# WB32F10x register map
File version: 1.2
CPU: CM3 r2p0, little endian, MPU, no FPU, 4 interrupt priority bits
Registers are 32-bit, read-write, reset 0x0 unless marked. A register's access mark holds for its fields unless they carry their own. Offsets are from the block's base; [hi:lo] are bit positions; {n}, {i} and the like mark numbered series.

## USB — Universal Serial Bus
Base 0x40014000
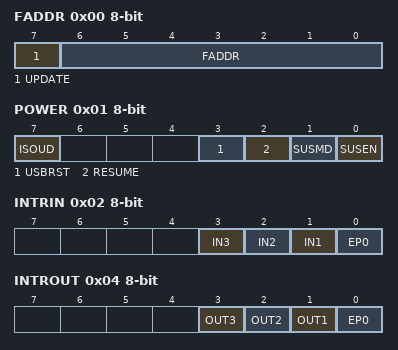
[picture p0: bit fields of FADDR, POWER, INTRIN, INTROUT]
0x00 FADDR 8-bit — Function address register
  [7] UPDATE — Function address update bit
  [6:0] FADDR — Function address
0x01 POWER 8-bit — USB power register
  [7] ISOUD — ISO update bit
  [3] USBRST — USB reset detect
  [2] RESUME
  [1] SUSMD — Suspend mode
  [0] SUSEN — Suspend mode enable
0x02 INTRIN 8-bit ro — IN endpoint interrupt flag register
  [3] IN3 — IN endpoint 3 interrupt flag
  [2] IN2 — IN endpoint 2 interrupt flag
  [1] IN1 — IN endpoint 1 interrupt flag
  [0] EP0 — Endpoint 0 interrupt flag
0x04 INTROUT 8-bit ro — OUT endpoint interrupt flag register
  [3] OUT3 — OUT endpoint 3 interrupt flag
  [2] OUT2 — OUT endpoint 2 interrupt flag
  [1] OUT1 — OUT endpoint 1 interrupt flag
  [0] EP0 — Endpoint 0 interrupt flag
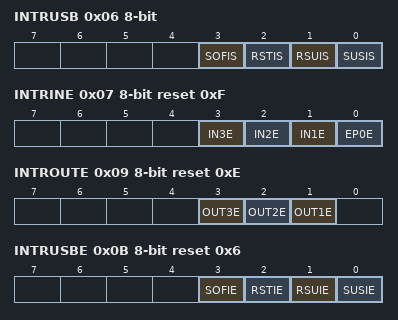
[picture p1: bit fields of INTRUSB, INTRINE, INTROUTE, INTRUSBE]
0x06 INTRUSB 8-bit ro — USB interrupt flag register
  [3] SOFIS — Start of frame interrupt flag
  [2] RSTIS — Reset interrupt flag
  [1] RSUIS — Restore interrupt flag
  [0] SUSIS — Suspend interrupt flag
0x07 INTRINE 8-bit reset 0xF — IN endpoint interrupt enable register
  [3] IN3E — IN endpoint 3 interrupt enable
  [2] IN2E — IN endpoint 2 interrupt enable
  [1] IN1E — IN endpoint 1 interrupt enable
  [0] EP0E — Endpoint 0 interrupt enable
0x09 INTROUTE 8-bit reset 0xE — OUT endpoint interrupt enable register
  [3] OUT3E — OUT endpoint 3 interrupt enable
  [2] OUT2E — OUT endpoint 2 interrupt enable
  [1] OUT1E — OUT endpoint 1 interrupt enable
0x0B INTRUSBE 8-bit reset 0x6 — USB interrupt enable register
  [3] SOFIE — Start of frame interrupt enable
  [2] RSTIE — Reset interrupt enable
  [1] RSUIE — Restore interrupt enable
  [0] SUSIE — Suspend interrupt enable
0x0C FRAMEL 8-bit ro — Frame low byte register
  [7:0] FRAMEL — Frame low byte
0x0D FRAMEH 8-bit ro — Frame high byte register
  [7:0] FRAMEL — Frame high byte
0x0E INDEX 8-bit — Endpoint index register
  [3:0] EPSEL — Endpoint selection
0x10 INMAXP 8-bit — Maxium packet size for IN endpoint register
  [7:0] INMAXP — Maximum Packet Size/transaction for IN endpoint
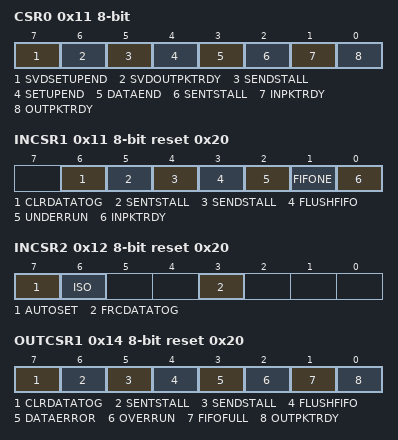
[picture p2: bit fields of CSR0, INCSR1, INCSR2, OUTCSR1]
0x11 CSR0 8-bit — Endpoint 0 control and status register
  [7] SVDSETUPEND — Clear SETUPEND bit
  [6] SVDOUTPKTRDY — Clear OUTPKTRDY bit
  [5] SENDSTALL — Set this bit to terminate the current transaction
  [4] SETUPEND
  [3] DATAEND
  [2] SENTSTALL — This bit is set by hardware when a STALL handshake is transmitted
  [1] INPKTRDY — Sets this bit after loading a data packet into the FIFO
  [0] OUTPKTRDY — Receive a data packet
0x11 INCSR1 8-bit reset 0x20 (alternate view of CSR0) — IN endpoint 1 control and status register
  [6] CLRDATATOG — Clear Data toggle bit
  [5] SENTSTALL — This bit is set by hardware when a STALL handshake is transmitted
  [4] SENDSTALL — Set this bit to issue a STALL handshake to an IN token
  [3] FLUSHFIFO
  [2] UNDERRUN
  [1] FIFONE — FIFO is not empty
  [0] INPKTRDY — Sets this bit after loading a data packet into the FIFO
0x12 INCSR2 8-bit reset 0x20 (alternate view of CSR0) — IN endpoint 2 control and status register
  [7] AUTOSET — INPKTRDY is set automatically
  [6] ISO — IN endpoint synchronous transfer
  [3] FRCDATATOG — Force data toggle
0x13 OUTMAXP 8-bit — Maxium packet size for OUT endpoint register
  [7:0] OUTMAXP — Maximum Packet Size/transaction for OUT endpoint
0x14 OUTCSR1 8-bit reset 0x20 — OUT endpoint 1 control and status register
  [7] CLRDATATOG — Clear Data toggle bit
  [6] SENTSTALL — This bit is set by hardware when a STALL handshake is transmitted
  [5] SENDSTALL — Set this bit to issue a STALL handshake
  [4] FLUSHFIFO
  [3] DATAERROR
  [2] OVERRUN
  [1] FIFOFULL — FIFO is full
  [0] OUTPKTRDY — Sets this bit after receiving a data packet
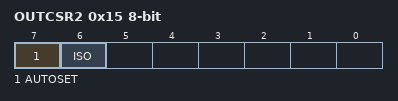
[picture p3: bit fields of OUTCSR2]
0x15 OUTCSR2 8-bit (alternate view of CSR0) — OUT endpoint 2 control and status register
  [7] AUTOSET — OUTPKTRDY is set automatically
  [6] ISO — OUT endpoint synchronous transfer
0x16 COUNT0 8-bit ro — Endpoint 0 data counter register
  [6:0] COUNT0 — Endpoint 0 data counter
0x16 OUTCOUNTL 8-bit ro (alternate view of COUNT0) — Endpoint 0 data counter low register
  [7:0] OUTCOUNTL — Endpoint 0 data counter low
0x17 OUTCOUNTH 8-bit ro — Endpoint 0 data counter high register
  [2:0] OUTCOUNTH — Endpoint 0 data counter high
{0x20+4i} FIFO{i} (i=0..3) — Endpoint {i} FIFO register
  [7:0] FIFODATA
